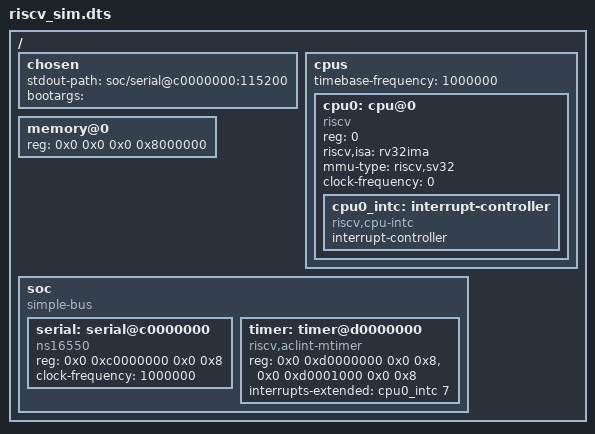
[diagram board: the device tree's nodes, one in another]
/dts-v1/;

/ {
    #address-cells = <2>;
    #size-cells = <2>;

    chosen {
        stdout-path = "soc/serial@c0000000:115200";
        bootargs = "";
    };

    cpus {
        #address-cells = <1>;
        #size-cells = <0>;
        timebase-frequency = <1000000>;
        cpu0: cpu@0 {
            device_type = "cpu";
            reg = <0>;
            status = "okay";
            compatible = "riscv";
            riscv,isa = "rv32ima";
            mmu-type = "riscv,sv32";
            clock-frequency = <0>;
            cpu0_intc: interrupt-controller {
                #interrupt-cells = <1>;
                compatible = "riscv,cpu-intc";
                interrupt-controller;
            };
        };
    };

    memory@0 {
        device_type = "memory";
        reg = <0x0 0x0 0x0 0x8000000>;   // 128 MB
    };

    soc {
        compatible = "simple-bus";
        #address-cells = <2>;
        #size-cells = <2>;
        ranges;

        serial: serial@c0000000 {
            device_type = "serial";
            compatible = "ns16550";
            reg = <0x0 0xc0000000 0x0 0x8>;
            clock-frequency = <1000000>;
        };

        timer: timer@d0000000 {
            compatible = "riscv,aclint-mtimer";
            reg = <0x0 0xd0000000 0x0 0x8>, <0x0 0xd0001000 0x0 0x8>;
            interrupts-extended = <&cpu0_intc 7>;
        };
    };
};

